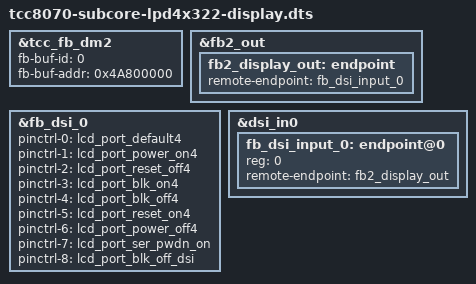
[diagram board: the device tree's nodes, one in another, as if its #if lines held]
// SPDX-License-Identifier: (GPL-2.0-or-later OR MIT)
/*
 * Copyright (C) 2023 Telechips Inc.
 */
#include <dt-bindings/display/tcc8070-lpd4x322-panel.h>
#include "tcc807x-subcore-disp-target-config.dtsi"
#include "tcc807x-disp.dtsi"
/*==============================================================================
 * TCC807x DISPLAY PATH
 * ---------------------------
 * FB2 : fb2<fb2_display_out> -> <fb_dsi_input_0>fb_dsi_0
 *	 RDMA8        -> DISP2 -> MUX2 -> DSI
==============================================================================*/
/* FB2 : CLUSTER */
&tcc_fb_dm2 {
	status = "okay";
	fb-buf-id = <0>;
	fb-buf-addr = <0x4A800000>;
};

/* fb2_display_out -> fb_dsi_input_0 */
&fb2_out {
	fb2_display_out: endpoint {
		remote-endpoint = <&fb_dsi_input_0>;
	};
};

&fb_dsi_0 {
	status = "okay";
	pinctrl-names = "default", "lcd_on", "reset_off",
			"blk_on", "blk_off", "reset_on", "lcd_off", "ser_pwdn_on", "blk_off_dsi";
	#if defined(LCD_PORT4_PWR) && defined(LCD_PORT4_RST) && \
	    defined(LCD_PORT4_BLK)
	pinctrl-0 = <&lcd_port_default4>;
	pinctrl-1 = <&lcd_port_power_on4>;
	pinctrl-2 = <&lcd_port_reset_off4>;
	pinctrl-3 = <&lcd_port_blk_on4>;
	pinctrl-4 = <&lcd_port_blk_off4>;
	pinctrl-5 = <&lcd_port_reset_on4>;
	pinctrl-6 = <&lcd_port_power_off4>;
	#endif
	#if defined(LCD_PORT_SER_PWDN)
	pinctrl-7 = <&lcd_port_ser_pwdn_on>;
	#endif
	pinctrl-8 = <&lcd_port_blk_off_dsi>;
};

/* fb2_display_out -> fb_dsi_input_0 */
&dsi_in0 {
	fb_dsi_input_0: endpoint@0 {
		reg = <0>;
		remote-endpoint = <&fb2_display_out>;
	};
};
